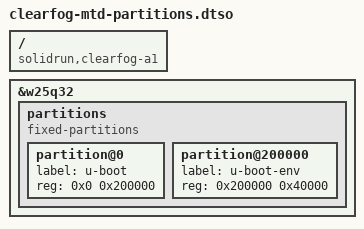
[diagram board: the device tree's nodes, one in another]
/dts-v1/;
/plugin/;

/ {
	compatible = "solidrun,clearfog-a1";
};

&w25q32 {
	partitions {
		compatible = "fixed-partitions";
		#address-cells = <1>;
		#size-cells = <1>;

		partition@0 {
			label = "u-boot";
			reg = <0x0 0x200000>;
		};

		partition@200000 {
			label = "u-boot-env";
			reg = <0x200000 0x40000>;
		};
	};
};
